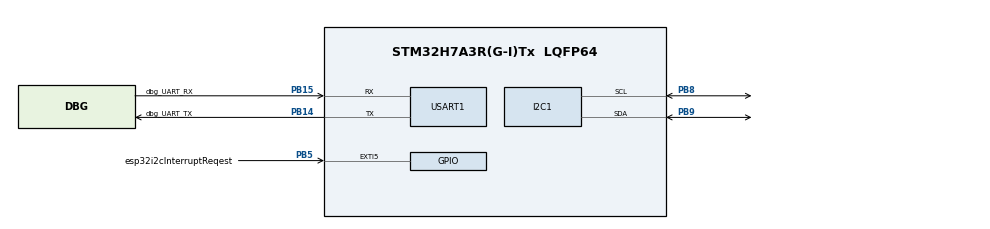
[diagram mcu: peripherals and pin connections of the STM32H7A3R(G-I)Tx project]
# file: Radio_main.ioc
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CORTEX_M7.default_mode_Activation=0
Dma.I2C1_RX.0.Direction=DMA_PERIPH_TO_MEMORY
Dma.I2C1_RX.0.EventEnable=DISABLE
Dma.I2C1_RX.0.FIFOMode=DMA_FIFOMODE_DISABLE
Dma.I2C1_RX.0.Instance=DMA1_Stream0
Dma.I2C1_RX.0.MemDataAlignment=DMA_MDATAALIGN_BYTE
Dma.I2C1_RX.0.MemInc=DMA_MINC_ENABLE
Dma.I2C1_RX.0.Mode=DMA_NORMAL
Dma.I2C1_RX.0.PeriphDataAlignment=DMA_PDATAALIGN_BYTE
Dma.I2C1_RX.0.PeriphInc=DMA_PINC_DISABLE
Dma.I2C1_RX.0.Polarity=HAL_DMAMUX_REQ_GEN_RISING
Dma.I2C1_RX.0.Priority=DMA_PRIORITY_LOW
Dma.I2C1_RX.0.RequestNumber=1
Dma.I2C1_RX.0.SignalID=NONE
Dma.I2C1_RX.0.SyncEnable=DISABLE
Dma.I2C1_RX.0.SyncPolarity=HAL_DMAMUX_SYNC_NO_EVENT
Dma.I2C1_RX.0.SyncRequestNumber=1
Dma.I2C1_RX.0.SyncSignalID=NONE
Dma.I2C1_TX.1.Direction=DMA_MEMORY_TO_PERIPH
Dma.I2C1_TX.1.EventEnable=DISABLE
Dma.I2C1_TX.1.FIFOMode=DMA_FIFOMODE_DISABLE
Dma.I2C1_TX.1.Instance=DMA1_Stream1
Dma.I2C1_TX.1.MemDataAlignment=DMA_MDATAALIGN_BYTE
Dma.I2C1_TX.1.MemInc=DMA_MINC_ENABLE
Dma.I2C1_TX.1.Mode=DMA_NORMAL
Dma.I2C1_TX.1.PeriphDataAlignment=DMA_PDATAALIGN_BYTE
Dma.I2C1_TX.1.PeriphInc=DMA_PINC_DISABLE
Dma.I2C1_TX.1.Polarity=HAL_DMAMUX_REQ_GEN_RISING
Dma.I2C1_TX.1.Priority=DMA_PRIORITY_LOW
Dma.I2C1_TX.1.RequestNumber=1
Dma.I2C1_TX.1.SignalID=NONE
Dma.I2C1_TX.1.SyncEnable=DISABLE
Dma.I2C1_TX.1.SyncPolarity=HAL_DMAMUX_SYNC_NO_EVENT
Dma.I2C1_TX.1.SyncRequestNumber=1
Dma.I2C1_TX.1.SyncSignalID=NONE
Dma.Request0=I2C1_RX
Dma.Request1=I2C1_TX
FREERTOS.Tasks01=defaultTask,24,128,StartDefaultTask,Default,NULL,Dynamic,NULL,NULL
FREERTOS.configENABLE_FPU=1
FREERTOS.configTOTAL_HEAP_SIZE=30720
FREERTOS.configUSE_NEWLIB_REENTRANT=1
FREERTOS.configUSE_TICKLESS_IDLE=1
I2C1.NoStretchMode=I2C_NOSTRETCH_ENABLE
I2C1.Timing=0x20B0CCFF
Mcu.Family=STM32H7
Mcu.Name=STM32H7A3R(G-I)Tx
Mcu.Package=LQFP64
NVIC.DMA1_Stream0_IRQn=true\:6\:0\:true\:false\:true\:false\:false\:true\:true
NVIC.DMA1_Stream1_IRQn=true\:6\:0\:true\:false\:true\:false\:false\:true\:true
NVIC.EXTI9_5_IRQn=true\:5\:0\:true\:false\:true\:true\:true\:true\:true
NVIC.I2C1_ER_IRQn=true\:6\:0\:true\:false\:true\:false\:true\:true\:true
NVIC.I2C1_EV_IRQn=true\:6\:0\:true\:false\:true\:false\:true\:true\:true
NVIC.PriorityGroup=NVIC_PRIORITYGROUP_4
NVIC.TIM1_UP_IRQn=true\:15\:0\:false\:false\:true\:false\:false\:true\:true
NVIC.TimeBase=TIM1_UP_IRQn
NVIC.TimeBaseIP=TIM1
NVIC.USART1_IRQn=true\:7\:0\:true\:false\:true\:false\:true\:true\:true
PA13.Mode=Trace_Asynchronous_SW
PA13.Signal=DEBUG_JTMS-SWDIO
PA14.Mode=Trace_Asynchronous_SW
PA14.Signal=DEBUG_JTCK-SWCLK
PB14.GPIO_Label=dbg_UART_TX
PB14.Mode=Asynchronous
PB14.Signal=USART1_TX
PB15.GPIO_Label=dbg_UART_RX
PB15.Mode=Asynchronous
PB15.Signal=USART1_RX
PB3.Mode=Trace_Asynchronous_SW
PB3.Signal=DEBUG_JTDO-SWO
PB5.GPIO_Label=esp32i2cInterruptReqest
PB5.GPIO_ModeDefaultEXTI=GPIO_MODE_IT_FALLING
PB5.Signal=GPXTI5
PB8.Mode=I2C
PB8.Signal=I2C1_SCL
PB9.Mode=I2C
PB9.Signal=I2C1_SDA
ProjectManager.HeapSize=0x200
ProjectManager.StackSize=0x400
ProjectManager.TargetToolchain=STM32CubeIDE
RCC.ADCFreq_Value=129000000
RCC.APB1Freq_Value=140000000
RCC.APB2Freq_Value=140000000
RCC.APB3Freq_Value=140000000
RCC.APB4Freq_Value=140000000
RCC.CDPPRE=RCC_APB3_DIV2
RCC.CDPPRE1=RCC_APB1_DIV2
RCC.CDPPRE2=RCC_APB2_DIV2
RCC.CortexFreq_Value=280000000
RCC.DIVM1=4
RCC.DIVN1=35
RCC.HCLKFreq_Value=280000000
RCC.PLL2FRACN=0
RCC.PLL3FRACN=0
RCC.PLLFRACN=0
RCC.SRDPPRE=RCC_APB4_DIV2
RCC.SYSCLKFreq_VALUE=280000000
RCC.SYSCLKSource=RCC_SYSCLKSOURCE_PLLCLK
RCC.USBFreq_Value=280000000
USART1.VirtualMode-Asynchronous=VM_ASYNC
VP_FREERTOS_VS_CMSIS_V2.Mode=CMSIS_V2
VP_SYS_VS_tim1.Mode=TIM1
board=custom

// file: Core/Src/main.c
/* USER CODE BEGIN Header */
/**
  ******************************************************************************
  * @file           : main.c
  * @brief          : Main program body
  ******************************************************************************
  * @attention
  *
  * Copyright (c) 2024 STMicroelectronics.
  * All rights reserved.
  *
  * This software is licensed under terms that can be found in the LICENSE file
  * in the root directory of this software component.
  * If no LICENSE file comes with this software, it is provided AS-IS.
  *
  ******************************************************************************
  */
/* USER CODE END Header */
#include "main.h"
#include "cmsis_os.h"
#include "dma.h"
#include "i2c.h"
#include "usart.h"
#include "gpio.h"

/* USER CODE BEGIN Includes */
//#include "hwConfigFile.h"
#include "freertos.h"
//#include "printfRedirect.h"
//#include "tasksFunctions.h"
#include "SileliS_code/tasksFunctionsCppWrapper.h".h"
/* USER CODE END Includes */

/* USER CODE BEGIN PTD */

/********************************************************************
 * @brief  [Krótki opis funkcji]
 *
 * [Dłuższy opis funkcji, w którym można wyjaśnić szczegóły działania,
 *  algorytmy, przypadki brzegowe itp.]
 *
 * @param  [parametr1] [Typ parametru] Opis pierwszego parametru.
 * @param  [parametr2] [Typ parametru] Opis drugiego parametru.
 * @param  [parametr3] [Typ parametru] Opis trzeciego parametru.
 *
 * @return [Typ zwracanej wartości] Opis tego, co funkcja zwraca.
 * @retval [wartość_1] Opis pierwszej możliwej wartości zwracanej.
 * @retval [wartość_2] Opis drugiej możliwej wartości zwracanej.
 *
 * @note   [Dodatkowe informacje, jeśli są istotne]
 * @warning [Ostrzeżenia dotyczące używania funkcji, jeśli istnieją]
 *******************************************************************/

/* USER CODE END PTD */

void SystemClock_Config(void);
void MX_FREERTOS_Init(void);

/* USER CODE BEGIN 0 */
//void delay_ms(uint32_t ms);
/* USER CODE END 0 */

int main(void)
{

  /* USER CODE BEGIN 1 */
	// convert to c++:  https://www.youtube.com/watch?v=Sk5XrgSaftk

  /* USER CODE END 1 */

  /* MCU Configuration--------------------------------------------------------*/

  /* Reset of all peripherals, Initializes the Flash interface and the Systick. */
  HAL_Init();

  /* Configure the system clock */
  SystemClock_Config();

  /* Initialize all configured peripherals */
  MX_GPIO_Init();
  MX_DMA_Init();
  MX_USART1_UART_Init();
  MX_I2C1_Init();
  /* USER CODE BEGIN 2 */

  startUpTask_CPPWrapper(NULL);

  /* USER CODE END 2 */

  /* Init scheduler */
  osKernelInitialize();

  /* Call init function for freertos objects (in cmsis_os2.c) */
  MX_FREERTOS_Init();

  /* Start scheduler */
  osKernelStart();

  /* We should never get here as control is now taken by the scheduler */

  /* Infinite loop */
  /* USER CODE BEGIN WHILE */
  while (1)
  {
	  vTaskDelay(portMAX_DELAY);
    /* USER CODE END WHILE */

  }
}

void SystemClock_Config(void)
{
  RCC_OscInitTypeDef RCC_OscInitStruct = {0};
  RCC_ClkInitTypeDef RCC_ClkInitStruct = {0};

  /*AXI clock gating */
  RCC->CKGAENR = 0xFFFFFFFF;

  /** Supply configuration update enable
  */
  HAL_PWREx_ConfigSupply(PWR_LDO_SUPPLY);

  /** Configure the main internal regulator output voltage
  */
  __HAL_PWR_VOLTAGESCALING_CONFIG(PWR_REGULATOR_VOLTAGE_SCALE0);

  while(!__HAL_PWR_GET_FLAG(PWR_FLAG_VOSRDY)) {}

  /** Initializes the RCC Oscillators according to the specified parameters
  * in the RCC_OscInitTypeDef structure.
  */
  RCC_OscInitStruct.OscillatorType = RCC_OSCILLATORTYPE_HSI;
  RCC_OscInitStruct.HSIState = RCC_HSI_DIV1;
  RCC_OscInitStruct.HSICalibrationValue = 64;
  RCC_OscInitStruct.PLL.PLLState = RCC_PLL_ON;
  RCC_OscInitStruct.PLL.PLLSource = RCC_PLLSOURCE_HSI;
  RCC_OscInitStruct.PLL.PLLM = 4;
  RCC_OscInitStruct.PLL.PLLN = 35;
  RCC_OscInitStruct.PLL.PLLP = 2;
  RCC_OscInitStruct.PLL.PLLQ = 2;
  RCC_OscInitStruct.PLL.PLLR = 2;
  RCC_OscInitStruct.PLL.PLLRGE = RCC_PLL1VCIRANGE_3;
  RCC_OscInitStruct.PLL.PLLVCOSEL = RCC_PLL1VCOWIDE;
  RCC_OscInitStruct.PLL.PLLFRACN = 0;
  if (HAL_RCC_OscConfig(&RCC_OscInitStruct) != HAL_OK)
  {
    Error_Handler();
  }

  /** Initializes the CPU, AHB and APB buses clocks
  */
  RCC_ClkInitStruct.ClockType = RCC_CLOCKTYPE_HCLK|RCC_CLOCKTYPE_SYSCLK
                              |RCC_CLOCKTYPE_PCLK1|RCC_CLOCKTYPE_PCLK2
                              |RCC_CLOCKTYPE_D3PCLK1|RCC_CLOCKTYPE_D1PCLK1;
  RCC_ClkInitStruct.SYSCLKSource = RCC_SYSCLKSOURCE_PLLCLK;
  RCC_ClkInitStruct.SYSCLKDivider = RCC_SYSCLK_DIV1;
  RCC_ClkInitStruct.AHBCLKDivider = RCC_HCLK_DIV1;
  RCC_ClkInitStruct.APB3CLKDivider = RCC_APB3_DIV2;
  RCC_ClkInitStruct.APB1CLKDivider = RCC_APB1_DIV2;
  RCC_ClkInitStruct.APB2CLKDivider = RCC_APB2_DIV2;
  RCC_ClkInitStruct.APB4CLKDivider = RCC_APB4_DIV2;

  if (HAL_RCC_ClockConfig(&RCC_ClkInitStruct, FLASH_LATENCY_6) != HAL_OK)
  {
    Error_Handler();
  }
}

void HAL_TIM_PeriodElapsedCallback(TIM_HandleTypeDef *htim)
{
  if (htim->Instance == TIM1) {
    HAL_IncTick();
  }
}

void Error_Handler(void)
{
  __disable_irq();
  while (1)
  {
  }
}
